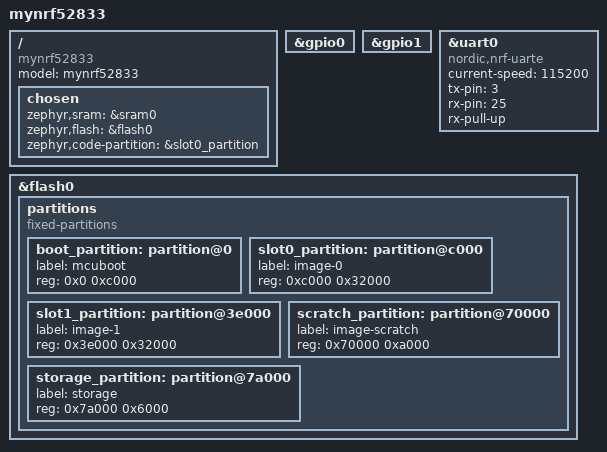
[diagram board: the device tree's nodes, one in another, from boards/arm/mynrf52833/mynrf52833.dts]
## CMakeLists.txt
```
# SPDX-License-Identifier: Apache-2.0

cmake_minimum_required(VERSION 3.20.0)

find_package(Zephyr REQUIRED HINTS $ENV{ZEPHYR_BASE})
project(my_test1)

include_directories(inc)
target_sources(app PRIVATE  
    src/main.c
    src/myuart.c
    src/mybluetooth.c
    src/uart_client.c
    src/direction_finding.c
    src/kalman_filter.c)
```

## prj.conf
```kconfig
# 配置文件


# 使能串口
CONFIG_SERIAL=y
CONFIG_NRFX_UARTE0=y
CONFIG_UART_ASYNC_API=y


# 使能蓝牙协议栈和GATT Client
CONFIG_BT=y
CONFIG_BT_CENTRAL=y
CONFIG_BT_GATT_CLIENT=y


# 蓝牙基础配置
CONFIG_BT_DEVICE_NAME="ble_thomas_client"
CONFIG_BT_SCAN=y
CONFIG_BT_GATT_DM=y
CONFIG_BT_SCAN_NAME_CNT=1
CONFIG_BT_SCAN_FILTER_ENABLE=y
# 蓝牙服务发现
CONFIG_HEAP_MEM_POOL_SIZE=2048


# 蓝牙寻向相关使能
CONFIG_BT_EXT_ADV=y
CONFIG_BT_OBSERVER=y
CONFIG_BT_PER_ADV_SYNC=y
# 使能蓝牙寻向特性
CONFIG_BT_DF=y
CONFIG_BT_DF_CONNECTIONLESS_CTE_RX=y
CONFIG_BT_CTLR=y
CONFIG_BT_LL_SW_SPLIT=y
CONFIG_BT_CTLR_ADV_EXT=y
CONFIG_BT_CTLR_SYNC_PERIODIC=y
CONFIG_BT_CTLR_DF=y
CONFIG_BT_CTLR_DF_ANT_SWITCH_TX=n
CONFIG_BT_CTLR_DF_ADV_CTE_TX=n
CONFIG_BT_CTLR_DF_PER_SCAN_CTE_NUM_MAX=16
# 关闭AOA，仅使用AOD
CONFIG_BT_CTLR_DF_ANT_SWITCH_RX=n
CONFIG_BT_DF_CTE_RX_AOA=n
# 配置多同步
CONFIG_BT_PER_ADV_SYNC_MAX=3


# 使用内部低速晶振（没有外部低速晶振）
CONFIG_CLOCK_CONTROL_NRF_K32SRC_RC=y

# 使能DSP库加速数据计算
CONFIG_CMSIS_DSP=y
CONFIG_CMSIS_DSP_MATRIX=y
CONFIG_NEWLIB_LIBC=y
CONFIG_CMSIS_DSP_STATISTICS=y
CONFIG_DEBUG_THREAD_INFO=y
CONFIG_DEBUG_OPTIMIZATIONS=y
CONFIG_NEWLIB_LIBC_FLOAT_PRINTF=y
```

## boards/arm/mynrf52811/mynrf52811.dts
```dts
// Copyright (c) 2022 Nordic Semiconductor ASA
// SPDX-License-Identifier: Apache-2.0

/dts-v1/;
#include <nordic/nrf52811_qfaa.dtsi>

/ {
	model = "mynrf52811";
	compatible = "mynrf52811";

	chosen {
		zephyr,sram = &sram0;
		zephyr,flash = &flash0;
		zephyr,code-partition = &slot0_partition;
	};
};

&uart0 {
	compatible = "nordic,nrf-uarte";
	status = "okay";
	current-speed = <115200>;
	tx-pin = <29>;
	rx-pin = <30>;
	rx-pull-up;
};


&flash0 {
	partitions {
		compatible = "fixed-partitions";
		#address-cells = <1>;
		#size-cells = <1>;

		boot_partition: partition@0 {
			label = "mcuboot";
			reg = <0x0 0xc000>;
		};
		slot0_partition: partition@c000 {
			label = "image-0";
			reg = <0xc000 0xa000>;
		};
		slot1_partition: partition@16000 {
			label = "image-1";
			reg = <0x16000 0xa000>;
		};
		scratch_partition: partition@20000 {
			label = "image-scratch";
			reg = <0x20000 0xa000>;
		};
		storage_partition: partition@2a000 {
			label = "storage";
			reg = <0x2a000 0x6000>;
		};
	};
};
```

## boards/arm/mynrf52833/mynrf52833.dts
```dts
// Copyright (c) 2022 Nordic Semiconductor ASA
// SPDX-License-Identifier: Apache-2.0

/dts-v1/;
#include <nordic/nrf52833_qiaa.dtsi>

/ {
	model = "mynrf52833";
	compatible = "mynrf52833";

	chosen {
		zephyr,sram = &sram0;
		zephyr,flash = &flash0;
		zephyr,code-partition = &slot0_partition;
	};
};


&gpio0 {
    status = "okay";
};

&gpio1 {
    status = "okay";
};


&uart0 {
	compatible = "nordic,nrf-uarte";
	status = "okay";
	current-speed = <115200>;
	tx-pin = <3>;
	rx-pin = <25>;
    // tx-pin = <25>;
	rx-pull-up;
};


&flash0 {
	partitions {
		compatible = "fixed-partitions";
		#address-cells = <1>;
		#size-cells = <1>;

		boot_partition: partition@0 {
			label = "mcuboot";
			reg = <0x0 0xc000>;
		};
		slot0_partition: partition@c000 {
			label = "image-0";
			reg = <0xc000 0x32000>;
		};
		slot1_partition: partition@3e000 {
			label = "image-1";
			reg = <0x3e000 0x32000>;
		};
		scratch_partition: partition@70000 {
			label = "image-scratch";
			reg = <0x70000 0xa000>;
		};
		storage_partition: partition@7a000 {
			label = "storage";
			reg = <0x7a000 0x6000>;
		};
	};
};
```

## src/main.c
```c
/**
 * @file main.c
 * @author hang chen (thomaszb.cn)
 * @brief 
 * @version 0.1
  * @date 2022-04-23
 * 
 * @copyright Copyright (c) 2022
 * 
 */
#include "zephyr.h"
#include "mybluetooth.h"
#include "myuart.h"
#include "direction_finding.h"
#include "uart_client.h"
#include "nrf_reg.h"
#include "arm_math.h"
#include "math.h"


/* 创建和32通信线程，优先级较低 */
K_THREAD_DEFINE(ble2stm32_thread_id, BLE2STM32_STACKSIZE, ble2stm32_thread, NULL, NULL,
		NULL, BLE2STM32_PRIORITY+1, 0, 0);

/* 创建接收基站1周期性广播线程 */
K_THREAD_DEFINE(perodic_adv_thread1_id, PERODIC_ADV_STACKSIZE, perodic_adv_thread1, NULL, NULL,
		NULL, PERODIC_ADV_PRIORITY, 0, 0);

/* 创建接收基站2周期性广播线程 */
K_THREAD_DEFINE(perodic_adv_thread2_id, PERODIC_ADV_STACKSIZE, perodic_adv_thread2, NULL, NULL,
		NULL, PERODIC_ADV_PRIORITY, 0, 0);

/* 创建接收基站3周期性广播线程 */
K_THREAD_DEFINE(perodic_adv_thread3_id, PERODIC_ADV_STACKSIZE, perodic_adv_thread3, NULL, NULL,
		NULL, PERODIC_ADV_PRIORITY, 0, 0);


void main(void)
{
	int err;
	int i=0 ;
	
	/* 串口初始化 */
 	err = uart_init();
	k_msleep(1000);
    printk("locater started\r\n");
    if (err){
		printk("uart init failed, errcode: %d\r\n", err);
	}

	/* 使能蓝牙协议栈 */
	err = bt_enable(NULL);
	if (err){
		printk("ble init failed, errcode: %d\r\n", err);
	}
	printk("ble init success!\r\n");
	ble_had_been_inited = 1;

	/* 使能扫描 */
	scan_init();
	bt_scan_enable();

	/* 使能direction finding */
	direction_finding_init();

    /* 发送蓝牙就绪信号量 */
	k_sem_give(&my_ble_ready);

	/* 开始AOD测量 */
	while (1){
		/* 使能扫描，若未连接，进行5ms扫描 */
		if (current_conn == NULL){
			bt_switch_conn();
			//bt_scan_enable();
			k_msleep(500);
		}
		if (gatt_had_been_find && current_conn){
			//bt_uart_client_read();
			//bt_uart_client_send("hello", 5);
		}
		if (i++ == 20){
			printk("Hello world\r\n");
		}
		k_msleep(2000);
	}
}
```

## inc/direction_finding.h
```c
/**
 * @file direction_finding.h
 * @author hang chen (thomaszb.cn)
 * @brief 
 * @version 0.1
 * @date 2022-04-23
 * 
 * @copyright Copyright (c) 2022
 * 
 */
#ifndef __DIRECTION_FINDING_H
#define __DIRECTION_FINDING_H

#include "bluetooth/scan.h"
#include "bluetooth/bluetooth.h"



#define SYNC_CREATE_TIMEOUT_INTERVAL_NUM 7
#define MY_GAP_ADV_MAX_DATA_LEN 3301
#define BLE2STM32_STACKSIZE 1024
#define BLE2STM32_PRIORITY 7
#define PERODIC_ADV_STACKSIZE 512
#define PERODIC_ADV_PRIORITY 7
// #define MYDIRECT_DEBUG

extern struct k_sem my_ble_ready;
extern struct k_sem sem_per_sync1;
extern struct k_sem sem_per_sync2;
extern struct k_sem sem_per_sync3;
extern volatile bool per_adv1_found;
extern volatile bool per_adv2_found;
extern volatile bool per_adv3_found;
extern uint32_t sync1_create_timeout_ms;
extern uint32_t sync2_create_timeout_ms;
extern uint32_t sync3_create_timeout_ms;


void direction_finding_init(void);
int delete_sync(uint8_t sync_num);
int enable_cte_rx(uint8_t sync_num);
int wait_sync_lost(uint8_t sync_num);
int wait_central_adv(uint8_t base_num);
int create_sync_handle(uint8_t sync_num);

void ble2stm32_thread(void);
void perodic_adv_thread1(void);
void perodic_adv_thread2(void);
void perodic_adv_thread3(void);

void scan_filter_not_match_cb(struct bt_scan_device_info*, bool);
void sync_cb(struct bt_le_per_adv_sync*, struct bt_le_per_adv_sync_synced_info*);
void term_cb(struct bt_le_per_adv_sync*, const struct bt_le_per_adv_sync_term_info*);
void cte_recv_cb(struct bt_le_per_adv_sync*, struct bt_df_per_adv_sync_iq_samples_report const*);
void sync_recv_cb(struct bt_le_per_adv_sync*, const struct bt_le_per_adv_sync_recv_info*, struct net_buf_simple*);


#endif
```

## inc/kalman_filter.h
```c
#ifndef __KALMAN_FILTER_H
#define __KALMAN_FILTER_H




float kalman_filter_rssi(int rssi);


#endif
```

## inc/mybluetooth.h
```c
/**
 * @file mybluetooth.h
 * @author hang chen (thomaszb.cn)
 * @brief 
 * @version 0.1
 * @date 2022-04-23
 * 
 * @copyright Copyright (c) 2022
 * 
 */
#ifndef __MYBLUETOOTH_H
#define __MYBLUETOOTH_H

#include "drivers/uart.h"
#include "bluetooth/bluetooth.h"
#include "bluetooth/hci.h"
#include "bluetooth/scan.h"
#include "bluetooth/conn.h"
#include <bluetooth/gatt_dm.h>

#define PEER_NAME_LEN_MAX 30
#define DEVICE_NAME CONFIG_BT_DEVICE_NAME
#define DEVICE_NAME_LEN (sizeof(DEVICE_NAME) - 1)


extern bool scan_enabled;
extern uint8_t ble_had_been_inited;
extern uint8_t gatt_had_been_find;
extern struct bt_conn *current_conn;

/* 外部调用函数 */
int scan_init(void);
void bt_switch_df(void);
int bt_scan_enable(void);
int bt_scan_disable(void);
void bt_switch_conn(void);
const char *phy2str(uint8_t phy);
void gatt_service_discover(struct bt_conn *conn);

/* 内部调用（回调函数） */
bool data_cb(struct bt_data *data, void *user_data);
void connected_cb(struct bt_conn *conn, uint8_t err);
void discovery_error_cb(struct bt_conn*, int, void*);
void discovery_complete_cb(struct bt_gatt_dm*, void*);
void scan_connecting_error_cb(struct bt_scan_device_info*);
void disconnected_cb(struct bt_conn *conn, uint8_t reason);
void discovery_service_not_found_cb(struct bt_conn*, void*);
void scan_connecting_cb(struct bt_scan_device_info*, struct bt_conn*);
void mtu_exchange_cb(struct bt_conn*, uint8_t, struct bt_gatt_exchange_params*);
void scan_filter_match_cb(struct bt_scan_device_info*, struct bt_scan_filter_match *, bool);


/**
 * @brief 将广播窗转化为ms
 *
 * @param interval 	：广播窗大小，单位0.625ms
 * @return uint32_t ：广播窗大小，单位ms
 */
static inline uint32_t adv_interval_to_ms(uint16_t interval)
{
	return (uint32_t)(interval*1.25);
}


#endif
```

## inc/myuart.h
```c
/**
 * @file myuart.h
 * @author hang chen (thomaszb.cn)
 * @brief 
 * @version 0.1
 * @date 2022-04-23
 * 
 * @copyright Copyright (c) 2022
 * 
 */
#ifndef __MYUART_H
#define __MYUART_H

#include "drivers/uart.h"

#define UART_BUF_SIZE 20
#define UART_RX_TIMEOUT 50

/* 串口数据格式 */
struct uart_data_t {
	void *fifo_reserved;
	uint8_t  data[UART_BUF_SIZE];
	uint16_t len;
};

extern const struct device *uart;

int uart_init(void);
void uart_cb(const struct device *dev, struct uart_event *evt, void *user_data);


#endif
```

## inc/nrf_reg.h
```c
/**
 * @file nrf_reg.h
 * @author your name (you@domain.com)
 * @brief 寄存器的相关定义
 * @version 0.1
 * @date 2022-04-29
 * 
 * @copyright Copyright (c) 2022
 * 
 */
#ifndef __NRF_REG_H
#define __NRF_REG_H

#include "stdint.h"

#define RADIO_BASS_ADD 0x40001000

#define DEFMODE (*(uint32_t *)(RADIO_BASS_ADD+0x900))



#endif
```

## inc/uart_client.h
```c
/**
 * @file uart_client.h
 * @author hang chen (thomaszb.cn)
 * @brief 
 * @version 0.1
 * @date 2022-04-23
 * 
 * @copyright Copyright (c) 2022
 * 
 */
#ifndef __UART_CLIENT_H
#define __UART_CLIENT_H

#include "mybluetooth.h"


/* 串口透传服务UUID */
#define UART_TP_UUID_VAL BT_UUID_128_ENCODE(0x4fafc201,0x1fb5, 0x459e, 0x8fcc, 0xc5c9c331914b)

/* 发送特征UUID */
#define UART_TX_UUID_VAL BT_UUID_128_ENCODE(0x4fafc203,0x1fb5, 0x459e, 0x8fcc, 0xc5c9c331914b)

/* 接收特征UUID */
#define UART_RX_UUID_VAL BT_UUID_128_ENCODE(0x4fafc204,0x1fb5, 0x459e, 0x8fcc, 0xc5c9c331914b)

#define BT_UUID_UART_TP        BT_UUID_DECLARE_128(UART_TP_UUID_VAL)
#define BT_UUID_UART_TX        BT_UUID_DECLARE_128(UART_TX_UUID_VAL)
#define BT_UUID_UART_RX        BT_UUID_DECLARE_128(UART_RX_UUID_VAL)


/* 蓝牙串口标志 */
enum bt_uart_send_status {
	/* 发送通知已启用 */
	BT_UART_SEND_STATUS_ENABLED,
	/* 发送通知未启用 */
	BT_UART_SEND_STATUS_DISABLED,

    BT_UART_INITIALIZED,
	BT_UART_TX_NOTIF_ENABLED,
	BT_UART_RX_WRITE_PENDING,
    BT_UART_READ_PENDING
};

typedef struct{
    /* 连接对象 */
    struct bt_conn *conn;
    /* 内部状态 */
    atomic_t state;

    uint16_t tx_handle;
    uint16_t rx_handle;
    uint16_t tx_ccc;
    /* 发送特征描述 */
	struct bt_gatt_subscribe_params tx_notif_params; 
    /* 接收特征描述 */
    struct bt_gatt_write_params rx_write_params;
    /* 读取 */
    struct bt_gatt_read_params read_params;
}bt_uart_client;

int bt_uart_client_read(void);
int bt_uart_subscribe_receive(void);
int get_uart_service(struct bt_gatt_dm *dm);
int bt_uart_client_send(const uint8_t *data, uint16_t len);



void bt_uart_client_send_cb(struct bt_conn *, uint8_t err, struct bt_gatt_write_params *);
uint8_t uart_tx_notify_cb(struct bt_conn *, struct bt_gatt_subscribe_params *, const void *, uint16_t);


#endif
```

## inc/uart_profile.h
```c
#ifndef __UART_PROFILE_H
#define __UART_PROFILE_H

#include <drivers/uart.h>
#include "bluetooth/uuid.h"
#include "bluetooth/gatt.h"


/* 串口透传服务UUID */
#define UART_TP_UUID_VAL BT_UUID_128_ENCODE(0x64f499cc,0x3411, 0x461d, 0x8055, 0x333d0bc7d33c)

/* 发送特征UUID */
#define UART_TX_UUID_VAL BT_UUID_128_ENCODE(0x64f499cd,0x3411, 0x461d, 0x8055, 0x333d0bc7d33c)

/* 接收特征UUID */
#define UART_RX_UUID_VAL BT_UUID_128_ENCODE(0x64f499ce,0x3411, 0x461d, 0x8055, 0x333d0bc7d33c)

#define BT_UUID_UART_TP        BT_UUID_DECLARE_128(UART_TP_UUID_VAL)
#define BT_UUID_UART_RX        BT_UUID_DECLARE_128(UART_TX_UUID_VAL)
#define BT_UUID_UART_TX        BT_UUID_DECLARE_128(UART_RX_UUID_VAL)


ssize_t ble_uart_receive_cb(struct bt_conn*, const struct bt_gatt_attr*, const void*, uint16_t, uint16_t, uint8_t);


#endif
```

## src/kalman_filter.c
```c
#include "kalman_filter.h"



/**
 * @brief			：使用卡尔曼滤波对rssi进行滤波
 * 
 * @param rssi 		：接收到的信号强度
 * @return float 	：rssi
 */
float kalman_filter_rssi(int rssi){
	/* 基本参数 */
	static float 	A				= -64.0867		;	/* RSSI参数（可以线性回归，可以1m处信号强度代替） */
	static float	rssi_forecast	= 0				;
	static float	n				= 0.4518		;	/* 传播因子 */
	static float	P				= 10			;	/* 协方差矩阵 */
	static float	K				= 0				;	/* 卡尔曼滤波参数 */ 
	
	/* 超参数 */
	static float	R				= 0.05			;	/* 观测噪声方差 */
	static float	Q				= 0.01	;	/* 过程噪声方差 */

	
	/* 预测lgd */
	rssi_forecast = rssi_forecast;
	
	/* 预测协方差矩阵 */
	P = P + Q;
	
	/* 更新卡尔曼滤波参数 */
	K = P / (P+R);
	
	/* 得到结果值 */
	rssi_forecast = rssi_forecast  + K*(rssi-rssi_forecast);
	
	/* 更新协方差矩阵 */
	P = (1-K)*P;
	
	return rssi_forecast;
}
```

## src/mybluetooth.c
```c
/**
 * @file mybluetooth.c
 * @author hang chen (thomaszb.cn)
 * @brief 
 * @version 0.1
 * @date 2022-04-23
 * 
 * @copyright Copyright (c) 2022
 * 
 */
#include "direction_finding.h"
#include "mybluetooth.h"
#include "myuart.h"
#include "uart_client.h"


/* 蓝牙初始化完成标志 */
bool scan_enabled = 0;
uint8_t ble_had_been_inited = 0;
uint8_t gatt_had_been_find = 0;

/* 连接句柄 */
struct bt_conn *current_conn = NULL;

/* 连接相关回调函数注册 */
BT_CONN_CB_DEFINE(conn_callbacks) = {
	.connected    = connected_cb,
	.disconnected = disconnected_cb,
};

/* 扫描相关回调函数初始化，注册在函数里面 */
BT_SCAN_CB_INIT(scan_callbacks, scan_filter_match_cb, scan_filter_not_match_cb,
		scan_connecting_error_cb, scan_connecting_cb);

/* 服务发现回调函数 */
const struct bt_gatt_dm_cb discovery_cb = {
	.completed         = discovery_complete_cb,
	.service_not_found = discovery_service_not_found_cb,
	.error_found       = discovery_error_cb,
};

/* 扫描参数 */
const struct bt_le_scan_param my_scan_param = {
	.type       = BT_HCI_LE_SCAN_ACTIVE,
	.options    = BT_LE_SCAN_OPT_FILTER_DUPLICATE,
	.interval   = BT_GAP_SCAN_FAST_INTERVAL,
	.window     = BT_GAP_SCAN_FAST_WINDOW,
    .timeout = 0U,
};
struct bt_scan_init_param my_scan_init_param = {
		.scan_param = &my_scan_param,
		.connect_if_match = 1,
};


/**
 * @brief 初始化扫描，主要是注册回调函数和过滤器初始化
 * 
 * @return int	：错误类型 
 */
int scan_init(void){
	int err;

	/* 初始化扫描参数，回调函数 */
	bt_scan_init(&my_scan_init_param);
	bt_scan_cb_register(&scan_callbacks);

	/* 添加过滤器 */
	err = bt_scan_filter_add(BT_SCAN_FILTER_TYPE_NAME, "dzyesp32");
	if (err) {
		printk("Scanning filters cannot be set (err %d)\r\n", err);
		return err;
	}
	
	/* 使能过滤器 */
	err = bt_scan_filter_enable(BT_SCAN_NAME_FILTER, true);
	if (err) {
		printk("Filters cannot be turned on (err %d)\r\n", err);
		return err;
	}

	printk("Scan module initialized\r\n");
	return 0;
}


/**
 * @brief 如果没有开始扫描，则启动扫描
 * 	
 * @return int	：错误类型 
 */
int bt_scan_enable(void){
	int err;
	
	/* 开始扫描 */
	err = bt_scan_start(BT_SCAN_TYPE_SCAN_ACTIVE);
	if (err == -120){
        scan_enabled = true;
		return 0;
	}
	else if (err) {
		printk("Starting scanning failed (err %d)\r\n", err);
		return err;
	}
	scan_enabled = true;
	printk("Scanning successfully started!\r\n");
	
	return 0;
}


/**
 * @brief 停止扫描
 * 
 * @return int	：错误类型 
 */
int bt_scan_disable(void){
	int err;

	err = bt_scan_stop();
	if (err == 120) {
		printk("scan aready disabled\r\n");
		return err;
	}
	else if (err){
		printk("scan disable failed (err %d)\r\n", err);
		return err;
	}
	printk("Scan disabled.\r\n");
	
	scan_enabled = false;
	return 0;
}


/**
 * @brief 开始寻找服务
 * 
 * @param conn 	：连接句柄
 */
void gatt_service_discover(struct bt_conn *conn)
{
	int err;

	if (conn != current_conn) {
		return;
	}

	err = bt_gatt_dm_start(conn, BT_UUID_UART_TP, &discovery_cb, NULL);

	if (err) {
		printk("could not start the discovery procedure, error "
			"code: %d\r\n", err);
	}
}


/**
 * @brief 连接成功回调函数，在该函数中进行连接参数的更行
 * 
 * @param conn 	:连接句柄
 * @param err 	:连接错误
 */
void connected_cb(struct bt_conn *conn, uint8_t err)
{
	if (err) {
		printk("Connection failed (err %u)\r\n", err);
		return;
	}
	printk("Connected!!\r\n");

	/**************** 初始化连接参数 ****************/
	static struct bt_gatt_exchange_params exchange_params;
	/* mtu交换 */
	exchange_params.func = mtu_exchange_cb;
	err = bt_gatt_exchange_mtu(conn, &exchange_params);
	if (err) {
		printk("MTU exchange failed (err %d)\r\n", err);
	}
	printk("MTU exchange succeed\r\n");
	
	gatt_service_discover(conn);

	/* 关闭自动连接 */
	// bt_scan_disable();
	// if (err){
	// 	printk("Stop failed (%d) \r\n", err);
	// }
	bt_scan_enable();
	bt_switch_df();
}


/**
 * @brief mtu交换的回调函数
 * 
 * @param conn 		：连接句柄
 * @param err 		：交换结果
 * @param params 	：交换的回调函数
 */
void mtu_exchange_cb(struct bt_conn *conn, uint8_t err, struct bt_gatt_exchange_params *params)
{
	if (!err) {
		printk("MTU exchange done\r\n");
	} else {
		printk("MTU exchange failed (err %" PRIu8 ")\r\n", err);
	}
}


/**
 * @brief 断开连接回调函数
 * 
 * @param conn 		:连接句柄
 * @param reason 	:断开原因
 */
void disconnected_cb(struct bt_conn *conn, uint8_t reason)
{
	printk("Disconnected (reason %u)\r\n", reason);
	bt_conn_unref(current_conn);
	current_conn = NULL;
	gatt_had_been_find = 0;
}


/**
 * @brief 匹配数据的回调函数，bt_data_parse函数将数据分块，回调函数解析这块数据
 * 
 * @param data 			：传入数据
 * @param user_data 	：解析完毕保存数据
 * @return true 		：成功
 * @return false 		：失败
 */
bool data_cb(struct bt_data *data, void *user_data)
{
	char *name = user_data;
	uint8_t len;

	switch (data->type) {
	case BT_DATA_NAME_SHORTENED:
	case BT_DATA_NAME_COMPLETE:
		len = MIN(data->data_len, PEER_NAME_LEN_MAX - 1);
		memcpy(name, data->data, len);
		name[len] = '\0';
		return false;
	default:
		return true;
	}
}


/**
 * @brief ble协议显示
 * 
 * @param phy 			：传入参数，phy标志
 * @return const char* 	：返回名称
 */
const char *phy2str(uint8_t phy)
{
	switch (phy) {
	case 0: return "No packets";
	case BT_GAP_LE_PHY_1M: return "LE 1M";
	case BT_GAP_LE_PHY_2M: return "LE 2M";
	case BT_GAP_LE_PHY_CODED: return "LE Coded";
	default: return "Unknown";
	}
}


/**
 * @brief 扫描回调函数中如果匹配成功的回调函数（弱定义，此应用中将在direction_finding.c里面重定义）
 * 
 * @param device_info 
 * @param filter_match 
 * @param connectable 
 */
__weak void scan_filter_match_cb(struct bt_scan_device_info *device_info,
			      struct bt_scan_filter_match *filter_match,
			      bool connectable)
{
	char le_addr[BT_ADDR_LE_STR_LEN];
	if (current_conn == NULL){
		bt_addr_le_to_str(device_info->recv_info->addr, le_addr, sizeof(le_addr));
		printk("[DEVICE]: %s, RSSI %i, connectable: %d , PHY: %d\r\n", le_addr, device_info->recv_info->rssi, connectable, device_info->recv_info->primary_phy);
	}
	
}


/**
 * @brief 连接失败回调函数
 * 
 * @param device_info 
 */
void scan_connecting_error_cb(struct bt_scan_device_info *device_info)
{
	printk("Connecting failed\r\n");
    bt_scan_enable();
	bt_switch_df();
}


/**
 * @brief 连接成功回调函数
 * 
 * @param device_info 
 */
void scan_connecting_cb(struct bt_scan_device_info *device_info,
			    struct bt_conn *conn)
{
	current_conn = bt_conn_ref(conn);
}


/**
 * @brief 切换为连接模式，找到对应设备并建立连接
 * 
 */
void bt_switch_conn(void){
	/* 打开自动连接 */
	//printk("switch to connected mode\r\n");
	bt_scan_conn_modify(true);
}


/**
 * @brief 切换为扫描CTE模式，不进行连接
 * 
 * @return int ：切换是否成功
 */
void bt_switch_df(void){
	/* 关闭自动连接 */
	printk("switch to direction finding mode... \r\n");
	bt_scan_conn_modify(false);
}


/**
 * @brief 服务发现成功回到函数
 * 
 * @param dm 		：服务发现句柄
 * @param context 	：传入参数
 */
void discovery_complete_cb(struct bt_gatt_dm *dm,
			       void *context)
{
	int err;
	printk("Service discovery completed\r\n");
	
	err = get_uart_service(dm);
	if (err){
		printk("find service error!\r\n");
		
	}
	else {
		gatt_had_been_find = 1;
	}

    //bt_uart_subscribe_receive();

    bt_gatt_dm_data_release(dm);
}


/**
 * @brief 服务发现未找到服务回调函数
 * 
 * @param conn 		：连接句柄
 * @param context 	：传入参数
 */
void discovery_service_not_found_cb(struct bt_conn *conn,
					void *context)
{
	printk("Service not found\r\n");
}


/**
 * @brief 服务发现错误回调函数
 * 
 * @param conn 		：连接句柄
 * @param err 		：出错类型
 * @param context 	：传入参数
 */
void discovery_error_cb(struct bt_conn *conn,
			    int err,
			    void *context)
{
	printk("Error while discovering GATT database: (%d)\r\n", err);
}
```

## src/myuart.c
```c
/**
 * @file myuart.c
 * @author hang chen (thomaszb.cn)
 * @brief 
 * @version 0.1
 * @date 2022-04-23
 * 
 * @copyright Copyright (c) 2022
 * 
 */
#include "myuart.h"

/* 串口设备 */
const struct device *uart;


/**
 * @breif: 串口初始化
 */
int uart_init(void){
	int err;
	static struct uart_data_t rx;

	/* 初始化串口设备 */
	uart = device_get_binding(DT_LABEL(DT_NODELABEL(uart0)));
	if (!uart) {
		return -ENXIO;
	}

	/* 设置串口回调函数 */
	err = uart_callback_set(uart, uart_cb, NULL);
	if (err) {
		return err;
	}

	/* 初始化串口接收 */
	return uart_rx_enable(uart, rx.data, sizeof(rx.data),
			      UART_RX_TIMEOUT);
}



/**
 * @brief 串口回调函数，目前没用
 * 
 * @param dev 
 * @param evt 
 * @param user_data 
 */
void uart_cb(const struct device *dev, struct uart_event *evt, void *user_data){

}


/**
 * @breif: 重定向printk函数，让printk打印向串口
 */
int arch_printk_char_out(int c)
{

	uart_poll_out(uart, (unsigned char)c);
	/* do nothing */
	return c;
}
```

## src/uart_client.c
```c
/**
 * @file uart_client.c
 * @author hang chen (thomaszb.cn)
 * @brief 用于解析串口透传服务
 * @version 0.1
 * @date 2022-04-23
 * 
 * @copyright Copyright (c) 2022
 * 
 */
#include "uart_client.h"
#include "myuart.h"

bt_uart_client  bt_uart_client_handle;


/**
 * @brief 得到串口服务的对象（句柄）
 * 
 * @param dm    ：服务发现描述符
 * @return int  ：0，发现成功；其他，错误代码
 */
int get_uart_service(struct bt_gatt_dm *dm){
    const struct bt_gatt_dm_attr *gatt_service_attr =
			bt_gatt_dm_service_get(dm);
	const struct bt_gatt_service_val *gatt_service =
			bt_gatt_dm_attr_service_val(gatt_service_attr);
	const struct bt_gatt_dm_attr *gatt_chrc;
	const struct bt_gatt_dm_attr *gatt_desc;

    /* 解析服务UUID */
    printk("finded service!\r\n");
    printk("uuid_type: %d\r\n", gatt_service->uuid->type);
    if (bt_uuid_cmp(gatt_service->uuid, BT_UUID_UART_TP)) {
		return -ENOTSUP;
	}
    printk("Getting handles from service.!\r\n");

	/* 解析TX特征 */
	gatt_chrc = bt_gatt_dm_char_by_uuid(dm, BT_UUID_UART_TX);
	if (!gatt_chrc) {
		printk("Missing TX characteristic.\r\n");
		return -EINVAL;
	}
	gatt_desc = bt_gatt_dm_desc_by_uuid(dm, gatt_chrc, BT_UUID_UART_TX); /* gatt描述符 */
	if (!gatt_desc) {
		printk("Missing TX value descriptor in characteristic.\r\n");
		return -EINVAL;
	}
	printk("Found handle for TX characteristic.\r\n");
    bt_uart_client_handle.tx_handle = gatt_desc->handle;


    /* 解析TX的客户端配置描述符（CCC） */
	gatt_desc = bt_gatt_dm_desc_by_uuid(dm, gatt_chrc, BT_UUID_GATT_CCC);
	if (!gatt_desc) {
		printk("Missing TX CCC in characteristic.\r\n");
		return -EINVAL;
	}
	printk("Found handle for CCC of TX characteristic.\r\n");
	bt_uart_client_handle.tx_ccc = gatt_desc->handle;


	/* 解析RX特征 */
	gatt_chrc = bt_gatt_dm_char_by_uuid(dm, BT_UUID_UART_RX);
	if (!gatt_chrc) {
		printk("Missing RX characteristic.\r\n");
		return -EINVAL;
	}
	gatt_desc = bt_gatt_dm_desc_by_uuid(dm, gatt_chrc, BT_UUID_UART_RX);
	if (!gatt_desc) {
		printk("Missing RX value descriptor in characteristic.\r\n");
		return -EINVAL;
	}
	printk("Found handle for RX characteristic.\r\n");
    bt_uart_client_handle.rx_handle = gatt_desc->handle;

    /* 保存该服务所属连接 */
    bt_uart_client_handle.conn = bt_gatt_dm_conn_get(dm);
    return 0;
}


/**
 * @brief 订阅接收服务（其实就是不断判断CCC那边）
 * 
 * @return int ：0，订阅成功；其他，订阅失败
 */
int bt_uart_subscribe_receive(void)
{
	int err;

	if (atomic_test_and_set_bit(&bt_uart_client_handle.state, BT_UART_SEND_STATUS_ENABLED)){
		return -EALREADY;
	}

	bt_uart_client_handle.tx_notif_params.notify = uart_tx_notify_cb;             /* 对方发notify的回调函数 */
	bt_uart_client_handle.tx_notif_params.value = BT_GATT_CCC_NOTIFY;
	bt_uart_client_handle.tx_notif_params.value_handle = bt_uart_client_handle.tx_handle;
    bt_uart_client_handle.tx_notif_params.ccc_handle = bt_uart_client_handle.tx_ccc;
	atomic_set_bit(bt_uart_client_handle.tx_notif_params.flags, 
                    BT_GATT_SUBSCRIBE_FLAG_VOLATILE);

    /* 订阅属性通知 */
	err = bt_gatt_subscribe(bt_uart_client_handle.conn, &bt_uart_client_handle.tx_notif_params);
    if (err) {
		printk("Subscribe failed (err %d)\r\n", err);
		atomic_clear_bit(&bt_uart_client_handle.state, BT_UART_TX_NOTIF_ENABLED);
	} else {
		printk("[SUBSCRIBED]\r\n");
	}

	return err;
}


/**
 * @brief 通知接收的回调函数
 * 
 * @param conn      ：连接句柄
 * @param params    ：gatt订阅服务的参数
 * @param data      ：接收的数据
 * @param length    ：数据的长度
 * @return uint8_t  ：是否继续键控通知
 */
uint8_t uart_tx_notify_cb(struct bt_conn *conn,
			struct bt_gatt_subscribe_params *params,
			const void *data, uint16_t length){
	if (!data) {
		printk("[UNSUBSCRIBED]\r\n");
		params->value_handle = 0;
		atomic_clear_bit(&bt_uart_client_handle.state, BT_UART_TX_NOTIF_ENABLED);
		return BT_GATT_ITER_STOP;
	}

	printk("[NOTIFICATION] data %p length %u\r\n", data, length);
	return BT_GATT_ITER_CONTINUE;
}


int bt_uart_client_send(const uint8_t *data, uint16_t len){
	int err;

	if (!bt_uart_client_handle.conn) {
		return -ENOTCONN;
	}

	if (atomic_test_and_set_bit(&bt_uart_client_handle.state, BT_UART_RX_WRITE_PENDING)) {
		return -EALREADY;
	}

	bt_uart_client_handle.rx_write_params.func = bt_uart_client_send_cb;
	bt_uart_client_handle.rx_write_params.handle = bt_uart_client_handle.rx_handle;
	bt_uart_client_handle.rx_write_params.offset = 0;
	bt_uart_client_handle.rx_write_params.data = data;
	bt_uart_client_handle.rx_write_params.length = len;

	err = bt_gatt_write(bt_uart_client_handle.conn, &bt_uart_client_handle.rx_write_params);
	if (err) {
		atomic_clear_bit(&bt_uart_client_handle.state, BT_UART_RX_WRITE_PENDING);
	}

	return err;
}


void bt_uart_client_send_cb(struct bt_conn *conn, uint8_t err,
		    struct bt_gatt_write_params *params)
{
	const void *data;
	uint16_t length;


	/* 制作回调所需的易失性数据的副本。 */
	data = params->data;
	length = params->length;

	atomic_clear_bit(&bt_uart_client_handle.state, BT_UART_RX_WRITE_PENDING);
}

uint8_t bt_uart_client_read_cb(struct bt_conn *conn, uint8_t err,
				    struct bt_gatt_read_params *params,
				    const void *data, uint16_t length)
{
	if (err){
		printk("read err (-%d)\r\n", err);
	}
	if (!data) {
		printk("\r\n");
		atomic_clear_bit(&bt_uart_client_handle.state, BT_UART_READ_PENDING);
		return BT_GATT_ITER_STOP;
	}

	uart_tx(uart, data, length, 0xffff);
	return BT_GATT_ITER_CONTINUE;
}


int bt_uart_client_read(void){
	int err;

	if (!bt_uart_client_handle.conn) {
		return -ENOTCONN;
	}

	if (atomic_test_and_set_bit(&bt_uart_client_handle.state, BT_UART_READ_PENDING)) {
		return -EALREADY;
	}

	bt_uart_client_handle.read_params.func = bt_uart_client_read_cb;
	bt_uart_client_handle.read_params.single.handle = bt_uart_client_handle.tx_handle;
	bt_uart_client_handle.read_params.single.offset = 0;
	bt_uart_client_handle.read_params.handle_count = 1;

	err = bt_gatt_read(bt_uart_client_handle.conn, &bt_uart_client_handle.read_params);
	if (err) {
		atomic_clear_bit(&bt_uart_client_handle.state, BT_UART_READ_PENDING);
	}

	return err;
}
```
